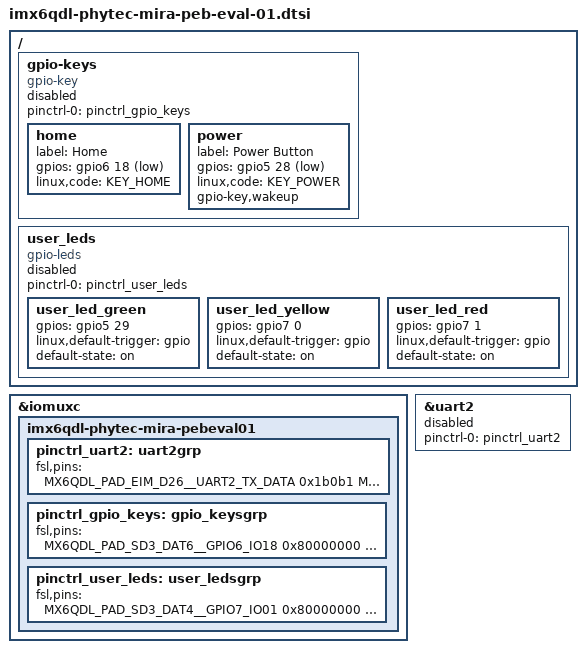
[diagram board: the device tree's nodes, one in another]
/*
 * Copyright (C) 2015 PHYTEC Messtechnik
 * Author: Christian Hemp <c.hemp@phytec.de> 
 *
 * The code contained herein is licensed under the GNU General Public
 * License. You may obtain a copy of the GNU General Public License
 * Version 2 or later at the following locations:
 *
 * http://www.opensource.org/licenses/gpl-license.html
 * http://www.gnu.org/copyleft/gpl.html
 */

#include <dt-bindings/input/input.h>

/ {
	gpio-keys {
		compatible = "gpio-key";
		pinctrl-names = "default";
		pinctrl-0 = <&pinctrl_gpio_keys>;
		status = "disabled";

		home {
			label = "Home";
			gpios = <&gpio6 18 GPIO_ACTIVE_LOW>;
			linux,code = <KEY_HOME>;
		};

		power {
			label = "Power Button";
			gpios = <&gpio5 28 GPIO_ACTIVE_LOW>;
			linux,code = <KEY_POWER>;
			gpio-key,wakeup;
		};
	};

	user_leds: user_leds {
		compatible = "gpio-leds";
		pinctrl-names = "default";
		pinctrl-0 = <&pinctrl_user_leds>;
		status = "disabled";

		user_led_green {
			gpios = <&gpio5 29 GPIO_ACTIVE_HIGH>;
			linux,default-trigger = "gpio";
			default-state = "on";
		};

		user_led_yellow {
			gpios = <&gpio7 0 GPIO_ACTIVE_HIGH>;
			linux,default-trigger = "gpio";
			default-state = "on";
		};

		user_led_red {
			gpios = <&gpio7 1 GPIO_ACTIVE_HIGH>;
			linux,default-trigger = "gpio";
			default-state = "on";
		};
	};	
};

&iomuxc {
	imx6qdl-phytec-mira-pebeval01 {
		pinctrl_uart2: uart2grp {
			fsl,pins = <
				MX6QDL_PAD_EIM_D26__UART2_TX_DATA	0x1b0b1
				MX6QDL_PAD_EIM_D27__UART2_RX_DATA	0x1b0b1
			>;
		};

		pinctrl_gpio_keys: gpio_keysgrp {
			fsl,pins = <
				MX6QDL_PAD_SD3_DAT6__GPIO6_IO18		0x80000000
				MX6QDL_PAD_CSI0_DAT10__GPIO5_IO28	0x80000000
			>;
		};

		pinctrl_user_leds: user_ledsgrp {
			fsl,pins = <
				MX6QDL_PAD_SD3_DAT4__GPIO7_IO01		0x80000000
				MX6QDL_PAD_SD3_DAT5__GPIO7_IO00		0x80000000
				MX6QDL_PAD_CSI0_DAT11__GPIO5_IO29	0x80000000
			>;
		};
	};
};

&uart2 {
	pinctrl-names = "default";
	pinctrl-0 = <&pinctrl_uart2>;
	status = "disabled";
};
